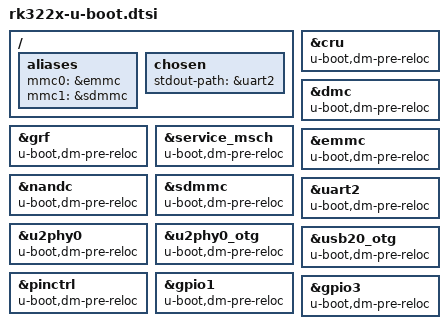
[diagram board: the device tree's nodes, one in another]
/*
 * (C) Copyright 2018 Rockchip Electronics Co., Ltd
 *
 * SPDX-License-Identifier:     GPL-2.0+
 */

/ {
	aliases {
		mmc0 = &emmc;
		mmc1 = &sdmmc;
	};

	chosen {
		stdout-path = &uart2;
	};
};

&cru {
	u-boot,dm-pre-reloc;
};

&dmc {
	u-boot,dm-pre-reloc;
};

&grf {
	u-boot,dm-pre-reloc;
};

&service_msch {
	u-boot,dm-pre-reloc;
};

&emmc {
	u-boot,dm-pre-reloc;
};

&nandc {
	u-boot,dm-pre-reloc;
};

&sdmmc {
	u-boot,dm-pre-reloc;
};

&uart2 {
	u-boot,dm-pre-reloc;
};

&u2phy0 {
	u-boot,dm-pre-reloc;
	status = "okay";
};

&u2phy0_otg {
	u-boot,dm-pre-reloc;
	status = "okay";
};

&usb20_otg {
	u-boot,dm-pre-reloc;
	status = "okay";
};

&pinctrl {
	u-boot,dm-pre-reloc;
	status = "okay";
};

&gpio1 {
	u-boot,dm-pre-reloc;
};

&gpio3 {
	u-boot,dm-pre-reloc;
	status = "okay";
};
